# liliumSOC1_sysctrl register map
Vendor: Nordic Semiconductor; Series: liliumSOC1; File version: 1
Registers are 32-bit, read-write, reset 0x0 unless marked. A register's access mark holds for its fields unless they carry their own. Offsets are from the block's base; [hi:lo] are bit positions; lines under a group give offsets from that group; 'fields as' and 'values as' point back to an identical list.

## VDET1V0_S — VDET1V0 peripheral
Base 0x5F976000
0x00 TASKS_PWRUP wo — Power up voltage detector
  [0] TASKS_PWRUP
    1=Trigger task
0x04 TASKS_PWRDOWN wo — Power down voltage detector
  [0] TASKS_PWRDOWN
    1=Trigger task
0x100 EVENTS_READY — Power up done
  [0] EVENTS_READY
    0=NotGenerated (Event not generated); 1=Generated (Event generated)
0x104 EVENTS_SETTLED — Settled flag for MODE handshake
  [0] EVENTS_SETTLED
    values as EVENTS_READY.EVENTS_READY
0x108 EVENTS_PWRGOOD — Power good detector detected voltage above threshold level
  [0] EVENTS_PWRGOOD
    values as EVENTS_READY.EVENTS_READY
0x10C EVENTS_PWRNOTGOOD — Power good detector detected voltage below threshold level
  [0] EVENTS_PWRNOTGOOD
    values as EVENTS_READY.EVENTS_READY
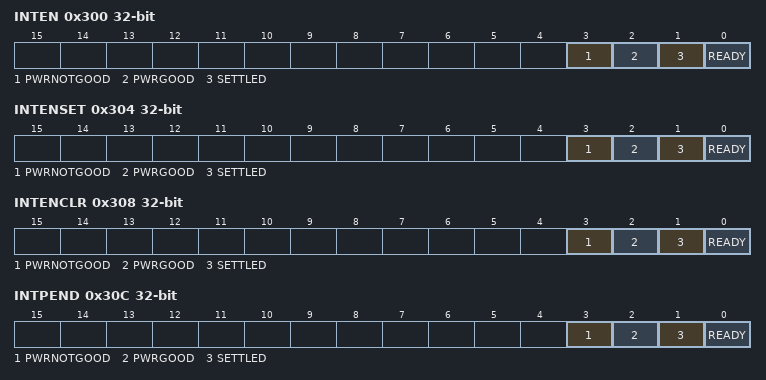
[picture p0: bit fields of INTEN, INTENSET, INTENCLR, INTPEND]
0x300 INTEN — Enable or disable interrupt
  [all] fields
    0=Disabled; 1=Enabled
  [3] PWRNOTGOOD — Enable or disable interrupt for event PWRNOTGOOD
  [2] PWRGOOD — Enable or disable interrupt for event PWRGOOD
  [1] SETTLED — Enable or disable interrupt for event SETTLED
  [0] READY — Enable or disable interrupt for event READY
0x304 INTENSET — Enable interrupt
  [all] fields
    on read: 0=Disabled (Read: Disabled); 1=Enabled (Read: Enabled) | on write: 1=Set (Enable)
  [3] PWRNOTGOOD — Write '1' to enable interrupt for event PWRNOTGOOD
  [2] PWRGOOD — Write '1' to enable interrupt for event PWRGOOD
  [1] SETTLED — Write '1' to enable interrupt for event SETTLED
  [0] READY — Write '1' to enable interrupt for event READY
0x308 INTENCLR — Disable interrupt
  [all] fields
    on read: 0=Disabled (Read: Disabled); 1=Enabled (Read: Enabled) | on write: 1=Clear (Disable)
  [3] PWRNOTGOOD — Write '1' to disable interrupt for event PWRNOTGOOD
  [2] PWRGOOD — Write '1' to disable interrupt for event PWRGOOD
  [1] SETTLED — Write '1' to disable interrupt for event SETTLED
  [0] READY — Write '1' to disable interrupt for event READY
0x30C INTPEND ro — Pending interrupts
  [all] fields
    on read: 0=NotPending (Read: Not pending); 1=Pending (Read: Pending)
  [3] PWRNOTGOOD — Read pending status of interrupt for event PWRNOTGOOD
  [2] PWRGOOD — Read pending status of interrupt for event PWRGOOD
  [1] SETTLED — Read pending status of interrupt for event SETTLED
  [0] READY — Read pending status of interrupt for event READY
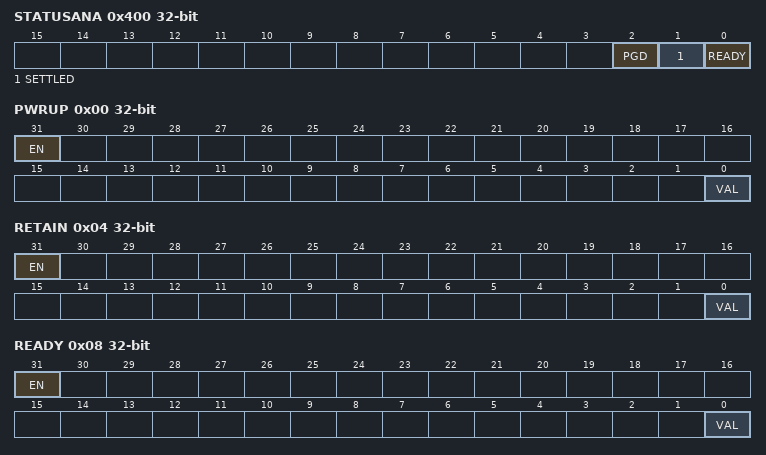
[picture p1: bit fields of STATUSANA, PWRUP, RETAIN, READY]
0x400 STATUSANA ro — Status of analog module output signals
  [2] PGD — Current value of the PGD signal from the analog module
  [1] SETTLED — Current value of the SETTLED signal from the analog module
  [0] READY — Current value of the READY signal from the analog module
0x410 CONFIG group — Unspecified
  0x00 CFG — Voltage detector configuration
    [0] PWRGOODHYST — Power good detector hysteresis setting
      0=HystLow (Hysteresis is 1.16 percent of the configured PGD level); 1=HystHigh (Hysteresis is 2.33 percent of the configured PGD level)
  0x04 PWRGOODLVL reset 0x11 — Power good detector threshold voltage level
    [5:0] VAL — Threshold voltage value
0x440 TRIM group — Unspecified
  0x00 PWRGOOD — Power good detector trimming
    [3:0] VAL — Threshold voltage trimming value.
0x480 MIRROR reset 0x1 — Enable LOCK for mirrored registers
  [0] LOCK — Lock for mirrored registers
    0=Disabled (Lock disabled); 1=Enabled (Lock enabled)
0x500 OVERRIDE group — Unspecified
  0x00 PWRUP — Override the PWRUP signal to the analog module
    [31] EN — Enable the override
      0=Disabled (Override is disabled); 1=Enabled (Override is enabled)
    [0] VAL — Override value for the signal
  0x04 RETAIN — Override the RETAIN signal to the analog module
    fields as OVERRIDE.PWRUP
  0x08 READY — Override the READY signal from the analog module
    [31] EN — Enable the override
      values as OVERRIDE.PWRUP.EN
    [0] VAL — Current value of the signal
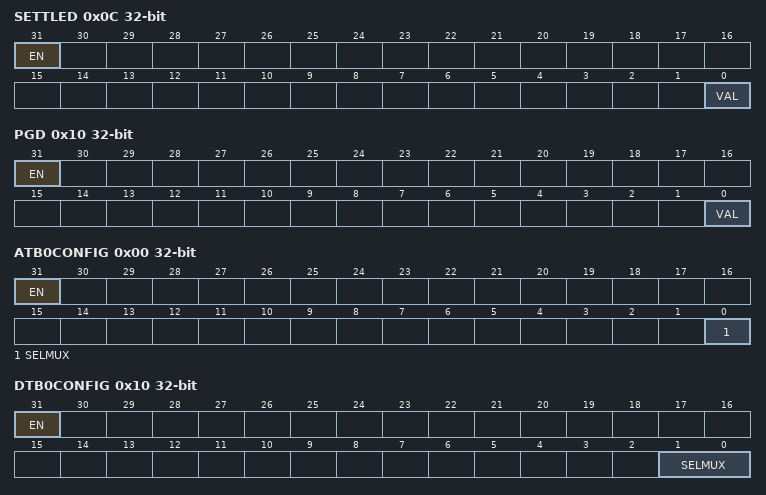
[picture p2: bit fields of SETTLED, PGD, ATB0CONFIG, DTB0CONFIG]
  0x0C SETTLED — Override the SETTLED signal from the analog module
    fields as OVERRIDE.READY
  0x10 PGD — Override the PGD signal from the analog module
    fields as OVERRIDE.READY
0x600 DFT group — Unspecified
  0x00 ATB0CONFIG — Analog Test Bus 0 (ATB0) configuration
    [31] EN — Enable the analog test bus
      0=Disabled (Analog test bus is disabled); 1=Enabled (Analog test bus is enabled)
    [0] SELMUX — Select multiplexer for ATB0
      0=Connect VSS to ATB0; 1=ConnectSenseVoltage (Use ATB0 as sense voltage instead of VDD_SENSE_1V0)
  0x04 ATB1CONFIG — Analog Test Bus 1 (ATB1) configuration
    [31] EN — Connect VREF_PGD to the analog test bus
      values as DFT.ATB0CONFIG.EN
  0x10 DTB0CONFIG — Digital Test Bus 0 (DTB0) configuration
    [31] EN — Enable the digital test bus
      0=Disabled (Digital test bus is disabled); 1=Enabled (Digital test bus is enabled)
    [1:0] SELMUX — Select multiplexer for DTB0
      0=READY_PGD_SW_0V8; 1=SETTLED_VDET1V0_AO_0V8; 2=PgdCmp (PGD comparator output); 3=PgdUnbuf (Unbuffered PGD, after deglitch filter)
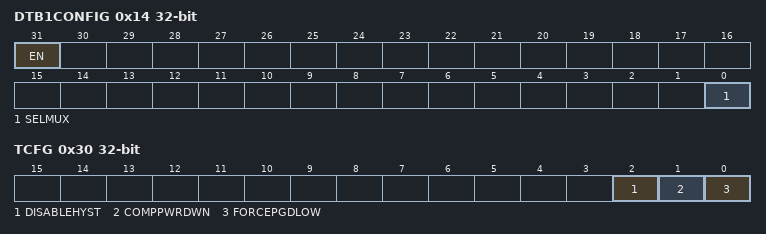
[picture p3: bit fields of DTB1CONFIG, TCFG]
  0x14 DTB1CONFIG — Digital Test Bus 1 (DTB1) configuration
    [31] EN — Enable the digital test bus
      values as DFT.DTB0CONFIG.EN
    [0] SELMUX — Select multiplexer for DTB1
      0=Spare0 (None selected, logic 0); 1=READY_VDET1V0_AO_0V8
  0x1C DTB3CONFIG — Digital Test Bus 3 (DTB3) configuration
    [27] PWRUPDELTEST — Enable the PWRUP delay test circuit
      0=Disabled (PWRUP delay test circuit is disabled); 1=Enabled (PWRUP delay test circuit is enabled)
  0x30 TCFG — Test mode configuration
    [all] fields
      0=Disabled (Normal operation); 1=Enabled (Test mode enabled)
    [2] DISABLEHYST — Disable comparator hysteresis
    [1] COMPPWRDWN — Power down PGD comparator
    [0] FORCEPGDLOW — Force VDET1V0_PGD_AO_0V8 low
